# nrf5340_application register map
Vendor: Nordic Semiconductor; Series: nrf53; File version: 1
CPU: CM33 r0p4, little endian, MPU, FPU, 3 interrupt priority bits, 69 interrupts
Registers are 32-bit, read-write, reset 0x0 unless marked. A register's access mark holds for its fields unless they carry their own. Offsets are from the block's base; [hi:lo] are bit positions; lines under a group give offsets from that group; {n}, {i} and the like mark numbered series; 'fields as' and 'values as' point back to an identical list.

## CACHEDATA_S — CACHEDATA
Base 0x00F00000
{0x0+0x20*i} SET[{i}] (i=0..255) group — Unspecified
  {0x0+0x10*j} WAY[{j}] (j=0..1) group — Unspecified
    {0x0+4k} DATA{k} (k=0..3) — Description cluster: Cache data bits [{32k+31}:{32k}] of SET[n], WAY[o].
      [31:0] Data

## CACHEINFO_S — CACHEINFO
Base 0x00F08000
{0x0+8i} SET[{i}] (i=0..255) group — Unspecified
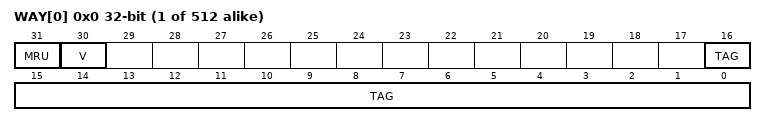
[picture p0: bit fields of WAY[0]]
  {0x0+4j} WAY[{j}] (j=0..1) — Description collection: Cache information for SET[n], WAY[o].
    [31] MRU ro — Most recently used way.
      0=Way0 was most recently used; 1=Way1 was most recently used
    [30] V ro — Valid bit
      0=Invalid cache line; 1=Valid cache line
    [16:0] TAG — Cache tag.

## TAD_S — Trace and debug control
Base 0xE0080000
0x04 CLOCKSTART wo — Start all trace and debug clocks.
  [0] START
    1=Start all trace and debug clocks
0x08 CLOCKSTOP wo — Stop all trace and debug clocks.
  [0] STOP
    1=Stop all trace and debug clocks
0x500 ENABLE — Enable debug domain and aquire selected GPIOs
  [0] ENABLE
    0=DISABLED (Disable debug domain and release selected GPIOs); 1=ENABLED (Enable debug domain and aquire selected GPIOs)
0x504 PSEL group — Unspecified
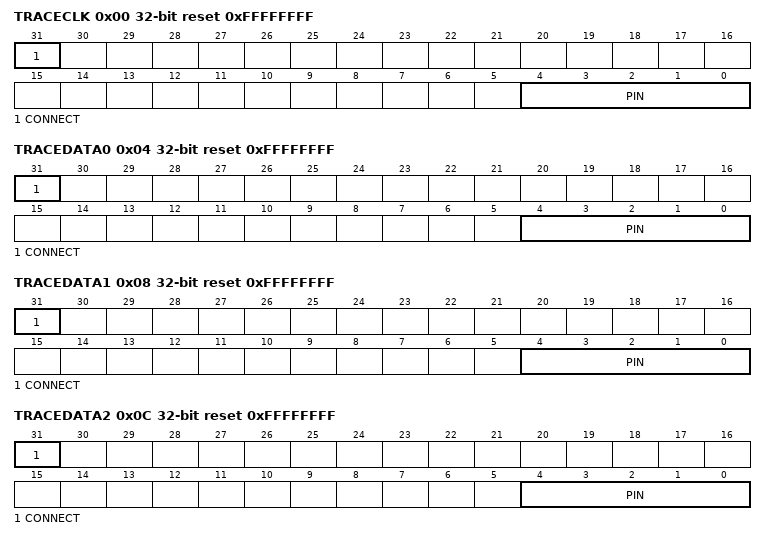
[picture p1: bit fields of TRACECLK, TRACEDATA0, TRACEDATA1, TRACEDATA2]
  0x00 TRACECLK reset 0xFFFFFFFF — Pin configuration for TRACECLK
    [31] CONNECT — Connection
      1=Disconnected; 0=Connected
    [4:0] PIN — Pin number
      12=TRACECLK pin
  0x04 TRACEDATA0 reset 0xFFFFFFFF — Pin configuration for TRACEDATA[0]
    [31] CONNECT — Connection
      1=Disconnected; 0=Connected
    [4:0] PIN — Pin number
      11=TRACEDATA0 pin
  0x08 TRACEDATA1 reset 0xFFFFFFFF — Pin configuration for TRACEDATA[1]
    [31] CONNECT — Connection
      1=Disconnected; 0=Connected
    [4:0] PIN — Pin number
      10=TRACEDATA1 pin
  0x0C TRACEDATA2 reset 0xFFFFFFFF — Pin configuration for TRACEDATA[2]
    [31] CONNECT — Connection
      1=Disconnected; 0=Connected
    [4:0] PIN — Pin number
      9=TRACEDATA2 pin
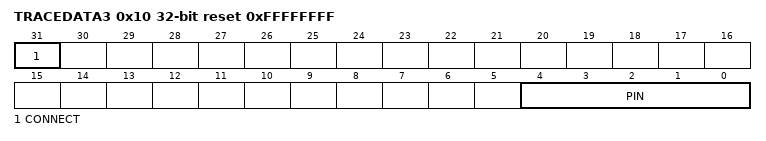
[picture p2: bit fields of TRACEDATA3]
  0x10 TRACEDATA3 reset 0xFFFFFFFF — Pin configuration for TRACEDATA[3]
    [31] CONNECT — Connection
      1=Disconnected; 0=Connected
    [4:0] PIN — Pin number
      8=TRACEDATA3 pin
0x518 TRACEPORTSPEED — Clocking options for the Trace Port debug interface Reset behavior is the same as debug components
  [1:0] TRACEPORTSPEED — Speed of Trace Port clock. Note that the TRACECLK pin output will be divided again by two from the Trace Port clock.
    0=64MHz (Trace Port clock is: 64MHz); 1=32MHz (Trace Port clock is: 32MHz); 2=16MHz (Trace Port clock is: 16MHz); 3=8MHz (Trace Port clock is: 8MHz)

## DCNF_NS — Domain configuration management 0
Base 0x40000000
Same registers: DCNF_S 0x50000000
0x420 CPUID ro — CPU ID of this subsystem
  [7:0] CPUID
{0x440+4i} EXTPERI[{i}] (i=0..0) group — Unspecified
  0x00 PROTECT — Description cluster: Control access for master connected to AMLI master port EXTPERI[n]
    [0] SLAVE0 — Control access to slave 0 of master EXTPERI[n]
      0=Allowed (Access to slave is allowed); 1=Blocked (Access to slave is blocked)
{0x460+4i} EXTRAM[{i}] (i=0..0) group — Unspecified
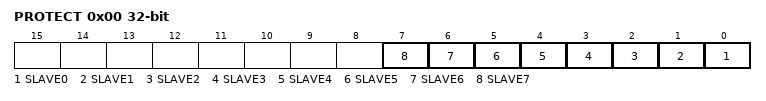
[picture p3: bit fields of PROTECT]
  0x00 PROTECT — Description cluster: Control access from master connected to AMLI master port EXTRAM[n]
    [all] fields
      values as EXTPERI[0].PROTECT.SLAVE0
    [n] SLAVE{n} (n=0..7) — Control access to slave {n} of master EXTRAM[n]
{0x480+4i} EXTCODE[{i}] (i=0..0) group — Unspecified
  0x00 PROTECT — Description cluster: Control access from master connected to AMLI master port EXTCODE[n]
    [0] SLAVE0 — Control access to slave 0 of master EXTCODE[n]
      values as EXTPERI[0].PROTECT.SLAVE0
